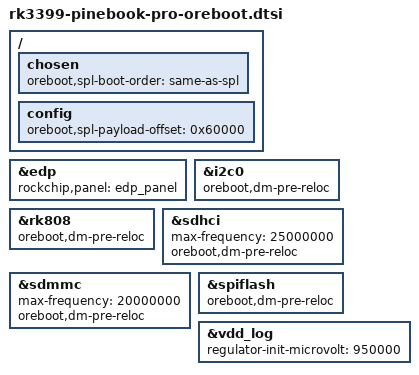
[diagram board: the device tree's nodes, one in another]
// SPDX-License-Identifier: GPL-2.0+
/*
 * Copyright (C) 2019 Peter Robinson <pbrobinson at gmail.com>
 */

#include "rk3399-oreboot.dtsi"
#include "rk3399-sdram-lpddr4-100.dtsi"

/ {
	chosen {
		oreboot,spl-boot-order = "same-as-spl", &sdhci, &spiflash, &sdmmc;
	};

	config {
		oreboot,spl-payload-offset = <0x60000>; /* @ 384KB */
	};
};

&edp {
	rockchip,panel = <&edp_panel>;
};

&i2c0 {
	oreboot,dm-pre-reloc;
};

&rk808 {
	oreboot,dm-pre-reloc;
};

&sdhci {
	max-frequency = <25000000>;
	oreboot,dm-pre-reloc;
};

&sdmmc {
	max-frequency = <20000000>;
	oreboot,dm-pre-reloc;
};

&spiflash {
	oreboot,dm-pre-reloc;
};

&vdd_log {
	regulator-init-microvolt = <950000>;
};
